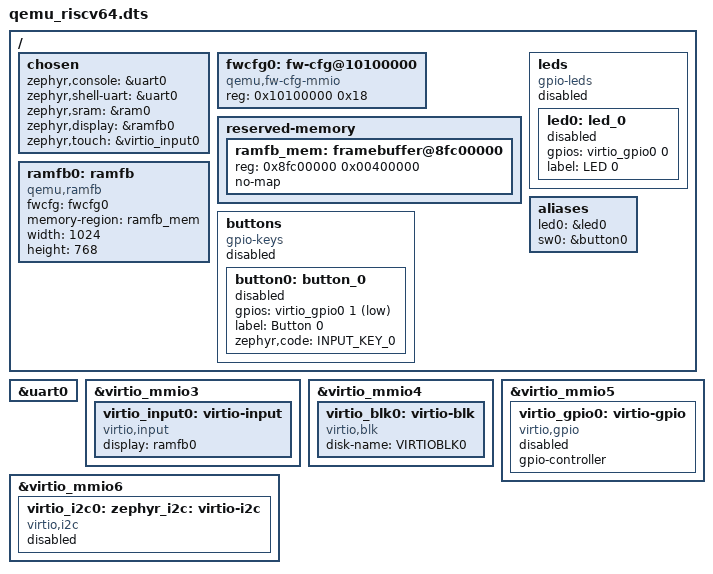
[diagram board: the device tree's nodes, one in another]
/* Copyright (c) 2019 BayLibre SAS */
/* SPDX-License-Identifier: Apache-2.0 */

/dts-v1/;

#include <qemu/virt-riscv64.dtsi>
#include <qemu/virt-riscv-plic.dtsi>

#include <qemu/virt-riscv-virtio-net.dtsi>

#include <zephyr/dt-bindings/gpio/gpio.h>
#include <zephyr/dt-bindings/input/input-event-codes.h>

/ {
	chosen {
		zephyr,console = &uart0;
		zephyr,shell-uart = &uart0;
		zephyr,sram = &ram0;
		zephyr,display = &ramfb0;
		zephyr,touch = &virtio_input0;
	};

	fwcfg0: fw-cfg@10100000 {
		compatible = "qemu,fw-cfg-mmio";
		reg = <0x10100000 0x18>;
		status = "okay";
	};

	reserved-memory {
		#address-cells = <1>;
		#size-cells = <1>;
		ranges;

		ramfb_mem: framebuffer@8fc00000 {
			reg = <0x8fc00000 0x00400000>; /* 4 MiB */
			no-map;
		};
	};

	ramfb0: ramfb {
		compatible = "qemu,ramfb";
		fwcfg = <&fwcfg0>;
		memory-region = <&ramfb_mem>;
		width = <1024>;
		height = <768>;
		status = "okay";
	};

	/*
	 * LED and button lines on the VIRTIO GPIO controller, disabled along
	 * with it.
	 */
	leds: leds {
		compatible = "gpio-leds";
		status = "disabled";

		led0: led_0 {
			gpios = <&virtio_gpio0 0 GPIO_ACTIVE_HIGH>;
			label = "LED 0";
			status = "disabled";
		};
	};

	buttons: buttons {
		compatible = "gpio-keys";
		status = "disabled";

		button0: button_0 {
			gpios = <&virtio_gpio0 1 GPIO_ACTIVE_LOW>;
			label = "Button 0";
			zephyr,code = <INPUT_KEY_0>;
			status = "disabled";
		};
	};

	aliases {
		led0 = &led0;
		sw0 = &button0;
	};
};

&uart0 {
	status = "okay";
};

&virtio_mmio3 {
	status = "okay";

	virtio_input0: virtio-input {
		compatible = "virtio,input";
		display = <&ramfb0>;
		status = "okay";
	};
};

/*
 * QEMU is given a virtio-blk device backed by a build-time disk image whenever
 * the disk driver is enabled, so nothing else is needed to use this one.
 */
&virtio_mmio4 {
	status = "okay";

	virtio_blk0: virtio-blk {
		compatible = "virtio,blk";
		disk-name = "VIRTIOBLK0";
		status = "okay";
	};
};

/*
 * The GPIO and I2C devices are vhost-user devices, and QEMU refuses to start
 * unless a backend is listening on their socket, so they are left disabled
 * until an application asks for them. See the board documentation.
 */
&virtio_mmio5 {
	virtio_gpio0: virtio-gpio {
		compatible = "virtio,gpio";
		gpio-controller;
		#gpio-cells = <2>;
		status = "disabled";
	};
};

&virtio_mmio6 {
	virtio_i2c0: virtio-i2c {
		compatible = "virtio,i2c";
		#address-cells = <1>;
		#size-cells = <0>;
		status = "disabled";
	};
};

zephyr_i2c: &virtio_i2c0 {};
